AUTOSAR XML (schema 00044)
package /E40_Platform_System_SystemPackage/Components
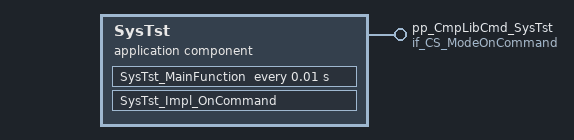
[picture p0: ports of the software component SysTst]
  application sw component type SysTst
    provide port pp_CmpLibCmd_SysTst: server-com-spec{operation=Impl_OnCommand, queue-length=1}, provided-interface=if_CS_ModeOnCommand
    behavior IB_SysTst: port-api-option{enable-take-address=false, indirect-api=false, port=pp_CmpLibCmd_SysTst}
      operation invoked event OIE_pp_CmpLibCmd_SysTst_SysTst_Impl_OnCommandTrigByImpl_OnCommand: start-on-event=SysTst_Impl_OnCommand, operation=pp_CmpLibCmd_SysTst.Impl_OnCommand
      timing event TESysTst_MainFunction: start-on-event=SysTst_MainFunction, period=0.01
      runnable SysTst_Impl_OnCommand: can-be-invoked-concurrently=true
      runnable SysTst_MainFunction: can-be-invoked-concurrently=true
  swc implementation IMPL_SysTst: behavior=IB_SysTst
